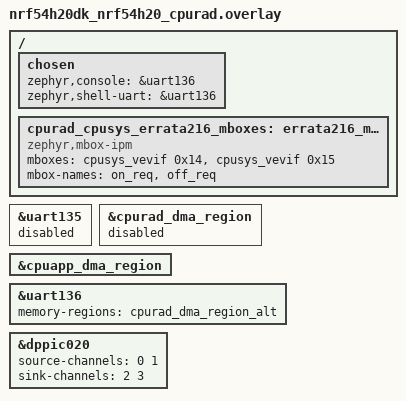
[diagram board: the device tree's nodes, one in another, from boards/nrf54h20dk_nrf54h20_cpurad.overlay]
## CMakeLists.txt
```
#
# Copyright (c) 2020 Nordic Semiconductor
#
# SPDX-License-Identifier: LicenseRef-Nordic-5-Clause
#

cmake_minimum_required(VERSION 3.20.0)

find_package(Zephyr REQUIRED HINTS $ENV{ZEPHYR_BASE})
project(NONE)

# Application sources
FILE(GLOB app_sources src/*.c)

# NORDIC SDK APP START
target_sources(app PRIVATE
	${app_sources}
)
# NORDIC SDK APP END
```

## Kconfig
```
#
# Copyright (c) 2020 Nordic Semiconductor
#
# SPDX-License-Identifier: LicenseRef-Nordic-5-Clause
#

mainmenu "Nordic Radio test sample"

config RADIO_TEST_USB
	bool "Radio Test shell over USB CDC ACM class"
	depends on SOC_NRF5340_CPUNET
	select EXPERIMENTAL
	help
	  Use USB instead of UART as the Radio Test shell transport.
	  For nRF5340 the USB from application core is used as communication interface.

config RADIO_TEST_POWER_CONTROL_AUTOMATIC
	bool "Automatic power control"
	depends on FEM
	default y
	help
	  Set SoC output power and front-end module gain to achieve Tx output power requested
	  by user. If the exact value cannot be achieved, power is set to closest value which does
	  not exceed the limits. If this option is disabled, user has to set SoC output power and
	  fem gain with separate commands.

config RADIO_TEST_RX_TIMEOUT
	int "RX packet reception timeout"
	default 10
	help
	  Specifies the time in seconds that the application waits for the first packet to be
	  received in RX mode when a specified number of packets are set to be received.
	  If the timeout is reached before the first packet is received, the radio will be disabled.

source "Kconfig.zephyr"
```

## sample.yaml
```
sample:
  description: Radio Test sample
  name: Radio Test
tests:
  sample.peripheral.radio_test:
    sysbuild: true
    build_only: true
    integration_platforms:
      - nrf52dk/nrf52832
      - nrf52840dk/nrf52840
      - nrf5340dk/nrf5340/cpunet
      - nrf7002dk/nrf5340/cpunet
      - nrf54l15dk/nrf54l05/cpuapp
      - nrf54l15dk/nrf54l10/cpuapp
      - nrf54l15dk/nrf54l15/cpuapp
      - nrf54lm20pdk/nrf54lm20a/cpuapp
      - nrf54lv10dk/nrf54lv10a/cpuapp
      - nrf54h20dk/nrf54h20/cpurad
    platform_allow:
      - nrf52dk/nrf52832
      - nrf52840dk/nrf52840
      - nrf5340dk/nrf5340/cpunet
      - nrf7002dk/nrf5340/cpunet
      - nrf54l15dk/nrf54l05/cpuapp
      - nrf54l15dk/nrf54l10/cpuapp
      - nrf54l15dk/nrf54l15/cpuapp
      - nrf54lm20pdk/nrf54lm20a/cpuapp
      - nrf54lv10dk/nrf54lv10a/cpuapp
      - nrf54h20dk/nrf54h20/cpurad
    tags:
      - ci_build
      - sysbuild
      - ci_samples_peripheral_radio_test
  sample.peripheral.radio_test.nrf5340_nrf21540:
    sysbuild: true
    build_only: true
    extra_args: SHIELD=nrf21540ek
    integration_platforms:
      - nrf5340dk/nrf5340/cpunet
    platform_allow: nrf5340dk/nrf5340/cpunet
    tags:
      - ci_build
      - sysbuild
      - ci_samples_peripheral_radio_test
  sample.peripheral.radio_test.nrf5340_usb:
    sysbuild: true
    build_only: true
    extra_args: FILE_SUFFIX=usb
    integration_platforms:
      - nrf5340dk/nrf5340/cpunet
    platform_allow: nrf5340dk/nrf5340/cpunet
    tags:
      - ci_build
      - sysbuild
      - ci_samples_peripheral_radio_test
  sample.peripheral.radio_test.nrf5340_nrf21540_usb:
    sysbuild: true
    build_only: true
    extra_args:
      - SHIELD=nrf21540ek
      - FILE_SUFFIX=usb
    integration_platforms:
      - nrf5340dk/nrf5340/cpunet
    platform_allow: nrf5340dk/nrf5340/cpunet
    tags:
      - ci_build
      - sysbuild
      - ci_samples_peripheral_radio_test
  sample.peripheral.radio_test.nrf5340_nrf21540.no_automatic_power:
    sysbuild: true
    build_only: true
    extra_args: SHIELD=nrf21540ek
    extra_configs:
      - CONFIG_RADIO_TEST_POWER_CONTROL_AUTOMATIC=n
    integration_platforms:
      - nrf5340dk/nrf5340/cpunet
    platform_allow: nrf5340dk/nrf5340/cpunet
    tags:
      - ci_build
      - sysbuild
      - ci_samples_peripheral_radio_test
  sample.peripheral.radio_test.nrf2220:
    sysbuild: true
    build_only: true
    extra_args: SHIELD=nrf2220ek
    integration_platforms:
      - nrf5340dk/nrf5340/cpunet
      - nrf54l15dk/nrf54l15/cpuapp
    platform_allow:
      - nrf5340dk/nrf5340/cpunet
      - nrf54l15dk/nrf54l15/cpuapp
    tags:
      - ci_build
      - sysbuild
      - ci_samples_peripheral_radio_test
  sample.peripheral.radio_test.nrf5340_nrf2220_usb:
    sysbuild: true
    build_only: true
    extra_args:
      - SHIELD=nrf2220ek
      - FILE_SUFFIX=usb
    integration_platforms:
      - nrf5340dk/nrf5340/cpunet
    platform_allow: nrf5340dk/nrf5340/cpunet
    tags:
      - ci_build
      - sysbuild
      - ci_samples_peripheral_radio_test
  sample.peripheral.radio_test.llvm:
    toolchain_allow: llvm
    sysbuild: true
    build_only: true
    integration_platforms:
      - nrf54l15dk/nrf54l15/cpuapp
      - nrf54lm20pdk/nrf54lm20a/cpuapp
    platform_allow:
      - nrf54l15dk/nrf54l15/cpuapp
      - nrf54lm20pdk/nrf54lm20a/cpuapp
    tags:
      - ci_build
      - sysbuild
      - ci_samples_peripheral_radio_test
```

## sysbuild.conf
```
#
# Copyright (c) 2024 Nordic Semiconductor
#
# SPDX-License-Identifier: LicenseRef-Nordic-5-Clause
#

SB_CONFIG_PARTITION_MANAGER=n
```

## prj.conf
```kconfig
#
# Copyright (c) 2020 Nordic Semiconductor
#
# SPDX-License-Identifier: LicenseRef-Nordic-5-Clause
#

CONFIG_CONSOLE_HANDLER=y
CONFIG_SHELL=y

CONFIG_DYNAMIC_INTERRUPTS=y

CONFIG_NRFX_TIMER0=y
CONFIG_NRFX_GPPI=y
CONFIG_CLOCK_CONTROL=y

CONFIG_ENTROPY_GENERATOR=y
CONFIG_NRF_SECURITY=y

CONFIG_FEM_AL_LIB=y
CONFIG_PICOLIBC_IO_FLOAT=y
CONFIG_SHELL_BACKEND_SERIAL_RX_RING_BUFFER_SIZE=1024
```

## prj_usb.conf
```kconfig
#
# Copyright (c) 2024 Nordic Semiconductor
#
# SPDX-License-Identifier: LicenseRef-Nordic-5-Clause
#

CONFIG_CONSOLE_HANDLER=y
CONFIG_SHELL=y

CONFIG_DYNAMIC_INTERRUPTS=y

CONFIG_NRFX_TIMER0=y
CONFIG_CLOCK_CONTROL=y

CONFIG_ENTROPY_GENERATOR=y
CONFIG_NRF_SECURITY=y

CONFIG_FEM_AL_LIB=y

CONFIG_RADIO_TEST_USB=y
```

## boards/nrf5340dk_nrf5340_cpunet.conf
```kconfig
#
# Copyright (c) 2022 Nordic Semiconductor
#
# SPDX-License-Identifier: LicenseRef-Nordic-5-Clause
#

CONFIG_CONSOLE_HANDLER=n
CONFIG_CONSOLE=n
CONFIG_SERIAL=n
CONFIG_UART_CONSOLE=n

CONFIG_SHELL_IPC=y
CONFIG_SHELL_LOG_BACKEND=y
CONFIG_SHELL_BACKEND_SERIAL=n
CONFIG_SHELL_PROMPT_IPC="radio_test:~$ "

CONFIG_LOG=y
CONFIG_LOG_PRINTK=y

CONFIG_MBOX=y
CONFIG_IPC_SERVICE=y
CONFIG_IPC_SERVICE_BACKEND_RPMSG=y

CONFIG_HEAP_MEM_POOL_SIZE=4096
```

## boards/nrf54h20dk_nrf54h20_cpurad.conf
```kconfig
#
# Copyright (c) 2024 Nordic Semiconductor
#
# SPDX-License-Identifier: LicenseRef-Nordic-5-Clause
#

# Disable the unsupported driver
CONFIG_NRFX_TIMER0=n

CONFIG_CONSOLE_HANDLER=y
CONFIG_SHELL=y

CONFIG_DYNAMIC_INTERRUPTS=y

CONFIG_NRFX_TIMER020=y

CONFIG_ENTROPY_GENERATOR=y
```

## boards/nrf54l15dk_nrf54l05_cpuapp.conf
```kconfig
#
# Copyright (c) 2024 Nordic Semiconductor
#
# SPDX-License-Identifier: LicenseRef-Nordic-5-Clause
#

# Disable the unsupported driver
CONFIG_NRFX_TIMER0=n

# Enable the necessary drivers
CONFIG_NRFX_TIMER10=y
```

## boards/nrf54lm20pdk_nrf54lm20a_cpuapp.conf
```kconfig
#
# Copyright (c) 2025 Nordic Semiconductor
#
# SPDX-License-Identifier: LicenseRef-Nordic-5-Clause
#

# Disable the unsupported driver
CONFIG_NRFX_TIMER0=n

# Enable the necessary drivers
CONFIG_NRFX_TIMER10=y
```

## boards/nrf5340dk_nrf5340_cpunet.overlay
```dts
/*
 * Copyright (c) 2022 Nordic Semiconductor ASA
 *
 * SPDX-License-Identifier: LicenseRef-Nordic-5-Clause
 */

/ {
	chosen {
		zephyr,shell-ipc = &ipc0;
	};
};

&uart0 {
	status = "disabled";
};
```

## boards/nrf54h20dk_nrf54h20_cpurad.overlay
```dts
/*
 * Copyright (c) 2024 Nordic Semiconductor ASA
 *
 * SPDX-License-Identifier: LicenseRef-Nordic-5-Clause
 */

 /{
	chosen {
		zephyr,console = &uart136;
		zephyr,shell-uart = &uart136;
	};
};

&uart135 {
	status = "disabled";
};

&cpurad_dma_region {
	status = "disabled";
};

/* Take Application's DMA region, which is larger and unused. */
cpurad_dma_region_alt: &cpuapp_dma_region {
	status = "okay";
};

&uart136 {
	status = "okay";
	memory-regions = <&cpurad_dma_region_alt>;
};

&dppic020 {
	status = "okay";
	source-channels = < 0 1 >;
	sink-channels = < 2 3 >;
};

/ {
	cpurad_cpusys_errata216_mboxes: errata216_mboxes {
		compatible = "zephyr,mbox-ipm";
		status = "okay";
		mboxes = < &cpusys_vevif 0x14 >, < &cpusys_vevif 0x15 >;
		mbox-names = "on_req", "off_req";
	};
};
```

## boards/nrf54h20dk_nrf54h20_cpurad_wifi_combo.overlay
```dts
/*
 * Copyright (c) 2024 Nordic Semiconductor ASA
 *
 * SPDX-License-Identifier: LicenseRef-Nordic-5-Clause
 */

&dppic020 {
	status = "okay";
	source-channels = < 0 1 >;
	sink-channels = < 2 3 >;
};
```

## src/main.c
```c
/*
 * Copyright (c) 2020 Nordic Semiconductor ASA
 *
 * SPDX-License-Identifier: LicenseRef-Nordic-5-Clause
 */

#include <zephyr/sys/printk.h>
#include <zephyr/drivers/clock_control.h>
#include <zephyr/drivers/clock_control/nrf_clock_control.h>
#if defined(NRF54L15_XXAA)
#include <hal/nrf_clock.h>
#endif /* defined(NRF54L15_XXAA) */
#if defined(CONFIG_CLOCK_CONTROL_NRF2)
#include <hal/nrf_lrcconf.h>
#endif
#include <nrf_erratas.h>
#if NRF54L_ERRATA_20_PRESENT
#include <hal/nrf_power.h>
#endif /* NRF54L_ERRATA_20_PRESENT */

/* Empty trim value */
#define TRIM_VALUE_EMPTY 0xFFFFFFFF

#if defined(CONFIG_CLOCK_CONTROL_NRF)
static void clock_init(void)
{
	int err;
	int res;
	struct onoff_manager *clk_mgr;
	struct onoff_client clk_cli;

	clk_mgr = z_nrf_clock_control_get_onoff(CLOCK_CONTROL_NRF_SUBSYS_HF);
	if (!clk_mgr) {
		printk("Unable to get the Clock manager\n");
		return;
	}

	sys_notify_init_spinwait(&clk_cli.notify);

	err = onoff_request(clk_mgr, &clk_cli);
	if (err < 0) {
		printk("Clock request failed: %d\n", err);
		return;
	}

	do {
		err = sys_notify_fetch_result(&clk_cli.notify, &res);
		if (!err && res) {
			printk("Clock could not be started: %d\n", res);
			return;
		}
	} while (err);

#if NRF54L_ERRATA_20_PRESENT
	if (nrf54l_errata_20()) {
		nrf_power_task_trigger(NRF_POWER, NRF_POWER_TASK_CONSTLAT);
	}
#endif /* NRF54L_ERRATA_20_PRESENT */

	printk("Clock has started\n");
}

#elif defined(CONFIG_CLOCK_CONTROL_NRF2)

static void clock_init(void)
{
	int err;
	int res;
	const struct device *radio_clk_dev =
		DEVICE_DT_GET_OR_NULL(DT_CLOCKS_CTLR(DT_NODELABEL(radio)));
	struct onoff_client radio_cli;

	/** Keep radio domain powered all the time to reduce latency. */
	nrf_lrcconf_poweron_force_set(NRF_LRCCONF010, NRF_LRCCONF_POWER_DOMAIN_1, true);

	sys_notify_init_spinwait(&radio_cli.notify);

	err = nrf_clock_control_request(radio_clk_dev, NULL, &radio_cli);

	do {
		err = sys_notify_fetch_result(&radio_cli.notify, &res);
		if (!err && res) {
			printk("Clock could not be started: %d\n", res);
			return;
		}
	} while (err == -EAGAIN);

#if NRF54L_ERRATA_20_PRESENT
	if (nrf54l_errata_20()) {
		nrf_power_task_trigger(NRF_POWER, NRF_POWER_TASK_CONSTLAT);
	}
#endif /* NRF54L_ERRATA_20_PRESENT */

	printk("Clock has started\n");
}

#if defined(CONFIG_SOC_SERIES_NRF54HX)
static void nrf54hx_radio_trim(void)
{
	/* Apply HMPAN-102 workaround for nRF54H series */
	*(volatile uint32_t *)0x5302C7E4 =
				(((*((volatile uint32_t *)0x5302C7E4)) & 0xFF000FFF) | 0x0012C000);

	/* Apply HMPAN-18 workaround for nRF54H series - load trim values*/
	if (*(volatile uint32_t *) 0x0FFFE458 != TRIM_VALUE_EMPTY) {
		*(volatile uint32_t *) 0x5302C734 = *(volatile uint32_t *) 0x0FFFE458;
	}

	if (*(volatile uint32_t *) 0x0FFFE45C != TRIM_VALUE_EMPTY) {
		*(volatile uint32_t *) 0x5302C738 = *(volatile uint32_t *) 0x0FFFE45C;
	}

	if (*(volatile uint32_t *) 0x0FFFE460 != TRIM_VALUE_EMPTY) {
		*(volatile uint32_t *) 0x5302C73C = *(volatile uint32_t *) 0x0FFFE460;
	}

	if (*(volatile uint32_t *) 0x0FFFE464 != TRIM_VALUE_EMPTY) {
		*(volatile uint32_t *) 0x5302C740 = *(volatile uint32_t *) 0x0FFFE464;
	}

	if (*(volatile uint32_t *) 0x0FFFE468 != TRIM_VALUE_EMPTY) {
		*(volatile uint32_t *) 0x5302C74C = *(volatile uint32_t *) 0x0FFFE468;
	}

	if (*(volatile uint32_t *) 0x0FFFE46C != TRIM_VALUE_EMPTY) {
		*(volatile uint32_t *) 0x5302C7D8 = *(volatile uint32_t *) 0x0FFFE46C;
	}

	if (*(volatile uint32_t *) 0x0FFFE470 != TRIM_VALUE_EMPTY) {
		*(volatile uint32_t *) 0x5302C840 = *(volatile uint32_t *) 0x0FFFE470;
	}

	if (*(volatile uint32_t *) 0x0FFFE474 != TRIM_VALUE_EMPTY) {
		*(volatile uint32_t *) 0x5302C844 = *(volatile uint32_t *) 0x0FFFE474;
	}

	if (*(volatile uint32_t *) 0x0FFFE478 != TRIM_VALUE_EMPTY) {
		*(volatile uint32_t *) 0x5302C848 = *(volatile uint32_t *) 0x0FFFE478;
	}

	if (*(volatile uint32_t *) 0x0FFFE47C != TRIM_VALUE_EMPTY) {
		*(volatile uint32_t *) 0x5302C84C = *(volatile uint32_t *) 0x0FFFE47C;
	}

	/* Apply HMPAN-103 workaround for nRF54H series*/
	if ((*(volatile uint32_t *) 0x5302C8A0 == 0x80000000) ||
		(*(volatile uint32_t *) 0x5302C8A0 == 0x0058120E)) {
		*(volatile uint32_t *) 0x5302C8A0 = 0x0058090E;
	}

	*(volatile uint32_t *) 0x5302C8A4 = 0x00F8AA5F;
	*(volatile uint32_t *) 0x5302C7AC = 0x8672827A;
	*(volatile uint32_t *) 0x5302C7B0 = 0x7E768672;
	*(volatile uint32_t *) 0x5302C7B4 = 0x0406007E;
}
#endif /* defined(CONFIG_SOC_SERIES_NRF54HX) */

#else
BUILD_ASSERT(false, "No Clock Control driver");
#endif /* defined(CONFIG_CLOCK_CONTROL_NRF) */

int main(void)
{
	printk("Starting Radio Test sample\n");

	clock_init();

#if defined(CONFIG_SOC_SERIES_NRF54HX)
	nrf54hx_radio_trim();
#endif

	return 0;
}
```

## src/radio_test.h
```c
/*
 * Copyright (c) 2020 Nordic Semiconductor ASA
 *
 * SPDX-License-Identifier: LicenseRef-Nordic-5-Clause
 */

#ifndef RADIO_TEST_H_
#define RADIO_TEST_H_

#include <zephyr/types.h>
#include <hal/nrf_radio.h>
#include <fem_al/fem_al.h>

#ifdef NRF53_SERIES
#ifndef RADIO_TXPOWER_TXPOWER_Pos3dBm
	#define RADIO_TXPOWER_TXPOWER_Pos3dBm (0x03UL)
#endif /* RADIO_TXPOWER_TXPOWER_Pos3dBm */

#ifndef RADIO_TXPOWER_TXPOWER_Pos2dBm
	#define RADIO_TXPOWER_TXPOWER_Pos2dBm (0x02UL)
#endif /* RADIO_TXPOWER_TXPOWER_Pos2dBm */

#ifndef RADIO_TXPOWER_TXPOWER_Pos1dBm
	#define RADIO_TXPOWER_TXPOWER_Pos1dBm (0x01UL)
#endif /* RADIO_TXPOWER_TXPOWER_Pos1dBm */
#endif /* NRF53_SERIES */

/** Maximum radio RX or TX payload. */
#define RADIO_MAX_PAYLOAD_LEN	256
/** IEEE 802.15.4 maximum payload length. */
#define IEEE_MAX_PAYLOAD_LEN	127
/** IEEE 802.15.4 minimum channel. */
#define IEEE_MIN_CHANNEL	11
/** IEEE 802.15.4 maximum channel. */
#define IEEE_MAX_CHANNEL	26

#define FEM_USE_DEFAULT_TX_POWER_CONTROL 0xFF

/**@brief Radio transmit and address pattern. */
enum transmit_pattern {
	/** Random pattern. */
	TRANSMIT_PATTERN_RANDOM,

	/** Pattern 11110000(F0). */
	TRANSMIT_PATTERN_11110000,

	/** Pattern 11001100(CC). */
	TRANSMIT_PATTERN_11001100,
};

/**@brief Radio test mode. */
enum radio_test_mode {
	/** TX carrier. */
	UNMODULATED_TX,

	/** Modulated TX carrier. */
	MODULATED_TX,

	/** RX carrier. */
	RX,

	/** TX carrier sweep. */
	TX_SWEEP,

	/** RX carrier sweep. */
	RX_SWEEP,

	/** Duty-cycled modulated TX carrier. */
	MODULATED_TX_DUTY_CYCLE,
};

/**@brief Radio test front-end module (FEM) configuration */
struct radio_test_fem {
	/* Front-end module radio ramp-up time in microseconds. */
	uint32_t ramp_up_time;

	/* Front-end module TX power control specific to given front-end module.
	 * For nRF21540 GPIO/SPI, this is a register value.
	 * For nRF21540 GPIO, this is MODE pin value.
	 */
	fem_tx_power_control tx_power_control;
};

/**@brief Radio test configuration. */
struct radio_test_config {
	/** Radio test type. */
	enum radio_test_mode type;

	/** Radio mode. Data rate and modulation. */
	nrf_radio_mode_t mode;

	union {
		struct {
			/** Radio output power. */
			int8_t txpower;

			/** Radio channel. */
			uint8_t channel;
		} unmodulated_tx;

		struct {
			/** Radio output power. */
			int8_t txpower;

			/** Radio transmission pattern. */
			enum transmit_pattern pattern;

			/** Radio channel. */
			uint8_t channel;

			/**
			 * Number of packets to transmit.
			 * Set to zero for continuous TX.
			 */
			uint32_t packets_num;

			/** Callback to indicate that TX is finished. */
			void (*cb)(void);
		} modulated_tx;

		struct {
			/** Radio transmission pattern. */
			enum transmit_pattern pattern;

			/** Radio channel. */
			uint8_t channel;

			/**
			 * Number of packets to be received.
			 * Set to zero for continuous RX.
			 */
			uint32_t packets_num;

			/** Callback to indicate that RX is finished. */
			void (*cb)(void);
		} rx;

		struct {
			/** Radio output power. */
			int8_t txpower;

			/** Radio start channel (frequency). */
			uint8_t channel_start;

			/** Radio end channel (frequency). */
			uint8_t channel_end;

			/** Delay time in milliseconds. */
			uint32_t delay_ms;
		} tx_sweep;

		struct {
			/** Radio start channel (frequency). */
			uint8_t channel_start;

			/** Radio end channel (frequency). */
			uint8_t channel_end;

			/** Delay time in milliseconds. */
			uint32_t delay_ms;
		} rx_sweep;

		struct {
			/** Radio output power. */
			int8_t txpower;

			/** Radio transmission pattern. */
			enum transmit_pattern pattern;

			/** Radio channel. */
			uint8_t channel;

			/** Duty cycle. */
			uint32_t duty_cycle;
		} modulated_tx_duty_cycle;
	} params;

#if CONFIG_FEM
	/* Front-end module (FEM) configuration. */
	struct radio_test_fem fem;
#endif /* CONFIG_FEM */
};

/**@brief Radio RX statistics. */
struct radio_rx_stats {
	/** Content of the last packet. */
	struct {
		/** Content of the last packet. */
		uint8_t *buf;

		/** Length of the last packet. */
		size_t len;
	} last_packet;

	/** Number of received packets with valid CRC. */
	uint32_t packet_cnt;
};

/**
 * @brief Function for initializing the Radio Test module.
 *
 * @param[in] config  Radio test configuration.
 *
 * @retval 0 If the operation was successful.
 *           Otherwise, a (negative) error code is returned.
 */
int radio_test_init(struct radio_test_config *config);

/**
 * @brief Function for starting radio test.
 *
 * @param[in] config  Radio test configuration.
 */
void radio_test_start(const struct radio_test_config *config);

/**
 * @brief Function for stopping ongoing test (Radio and Timer operations).
 *
 * @param[in] type  Radio test mode.
 */
void radio_test_cancel(enum radio_test_mode type);

/**
 * @brief Function for get RX statistics.
 *
 * @param[out] rx_stats RX statistics.
 */
void radio_rx_stats_get(struct radio_rx_stats *rx_stats);

/**
 * @brief Function for toggling the DC/DC converter state.
 *
 * @param[in] dcdc_state  DC/DC converter state.
 */
void toggle_dcdc_state(uint8_t dcdc_state);

#endif /* RADIO_TEST_H_ */
```
